# mc5_target_db register map
Vendor: Texas Instruments
Peripheral module from a debugger description file (folder iva2_arp32).
Address unit: 16 bits
Registers are 32-bit, read-write, reset 0x0 unless marked. A register's access mark holds for its fields unless they carry their own. Offsets are as the file gives them; lines under a group give offsets from that group; [hi:lo] are bit positions; {n}, {i} and the like mark numbered series; 'fields as' and 'values as' point back to an identical list; <NAME> marks a mode.

## DSS — ipxact12_to_ccs_generated
0x00 __ALL___SL2_BUF_ADDR_SKIP access per field reset 0x6000 — Skip Pred MB Base Address
  [21:0] BUF_ADDR rw — SL2 Base Address (128b word aligned) for Skip Pred MB
0x04 __ALL___SL2_BUF_ADDR_MBHDRINFO_TOP access per field — MB Info (Part-I) Base Address TOP
  [21:0] BUF_ADDR rw — SL2 Base Address (128b word aligned) for MB Info (Part-I) TOP
0x08 __ALL___SL2_BUF_ADDR_MBHDRINFO_BOT access per field reset 0x800 — MB Info (Part-I) Base Address BOT
  [21:0] BUF_ADDR rw — SL2 Base Address (128b word aligned) for MB Info (Part-I) BOT
0x0C __ALL___SL2_BUF_ADDR_MBMVINFO_TOP access per field reset 0x1000 — MV Info (Part-II) Base Address TOP
  [21:0] BUF_ADDR rw — SL2 Base Address (128b word aligned) for MV Info (Part-II) TOP
0x10 __ALL___SL2_BUF_ADDR_MBMVINFO_BOT access per field reset 0x1800 — MV Info (Part-II) Base Address BOT
  [21:0] BUF_ADDR rw — SL2 Base Address (128b word aligned) for MV Info (Part-II) BOT
0x14 __ALL___SL2_BUF_ADDR_SLICEINFO access per field reset 0x2000 — Slice Info Base Address
  [21:0] BUF_ADDR rw — SL2 Base Address (128b word aligned) for Slice Info
0x18 __ALL___SL2_BUF_ADDR_SLICEEXPWEIGHTTABLE access per field reset 0x3000 — Weighted Prediction Paremeters Base Address
  [21:0] BUF_ADDR rw — SL2 Base Address (128b word aligned) for Weighted Prediction Paremeters
0x1C __ALL___SL2_BUF_ADDR_SLICERPL access per field reset 0x4000 — Reference Picture List Base Address
  [21:0] BUF_ADDR rw — SL2 Base Address (128b word aligned) for Reference Picture List
0x20 __ALL___SL2_BUF_ADDR_PICREFFRAMEINFO access per field reset 0x5000 — Reference Frame Info Base Address
  [21:0] BUF_ADDR rw — SL2 Base Address (128b word aligned) for Reference Frame Info
0x24 __ALL___SL2_BUF_ADDR_RFPB access per field — Reference Frame Parameter Buffer Base Address
  [21:0] BUF_ADDR rw — SL2 Base Address for Reference Frame Parameter Buffer
{0x28+4i} __ALL___SL2_BUF_ADDR_Y_VC_R{i} access per field (i=0..3) — Luma Vertical Cache Ref={i} SL2 Base Address
  [21:0] BUF_ADDR rw — SL2 Base Address for Luma Vertical Cache Ref={i}
{0x48+4i} __ALL___SL2_BUF_ADDR_UV_VC_R{i} access per field (i=0..3) — Chroma Vertical Cache Ref={i} SL2 Base Address
  [21:0] BUF_ADDR rw — SL2 Base Address for Chroma Vertical Cache Ref={i}
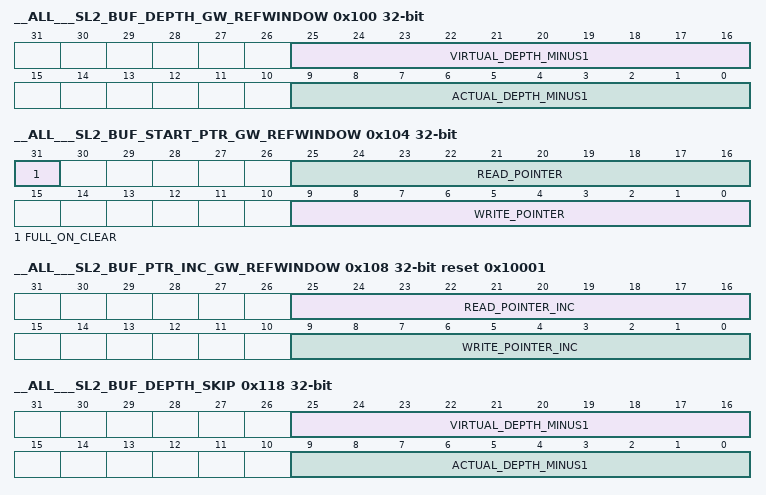
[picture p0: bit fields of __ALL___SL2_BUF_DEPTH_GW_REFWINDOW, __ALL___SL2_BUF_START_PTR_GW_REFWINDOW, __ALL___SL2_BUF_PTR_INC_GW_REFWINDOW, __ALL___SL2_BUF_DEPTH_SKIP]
0x100 __ALL___SL2_BUF_DEPTH_GW_REFWINDOW access per field — BC Control Parameters for Luma Growing Window Reference Pixel in SL2 fetched by iME
  [25:16] VIRTUAL_DEPTH_MINUS1 rw, [9:0] ACTUAL_DEPTH_MINUS1 rw
0x104 __ALL___SL2_BUF_START_PTR_GW_REFWINDOW access per field — BC Pointer Parameters for Luma Growing Window Reference Pixel in SL2 fetched by iME
  [31] FULL_ON_CLEAR rw, [25:16] READ_POINTER rw, [9:0] WRITE_POINTER rw
0x108 __ALL___SL2_BUF_PTR_INC_GW_REFWINDOW access per field reset 0x10001 — BC Pointer Increment Parameters for Luma Growing Window Reference Pixel in SL2 fetched by iME
  [25:16] READ_POINTER_INC rw, [9:0] WRITE_POINTER_INC rw
0x118 __ALL___SL2_BUF_DEPTH_SKIP access per field — BC Control Parameters for Luma Skip Pred Pixel in SL2 produced by iME
  [25:16] VIRTUAL_DEPTH_MINUS1 rw, [9:0] ACTUAL_DEPTH_MINUS1 rw
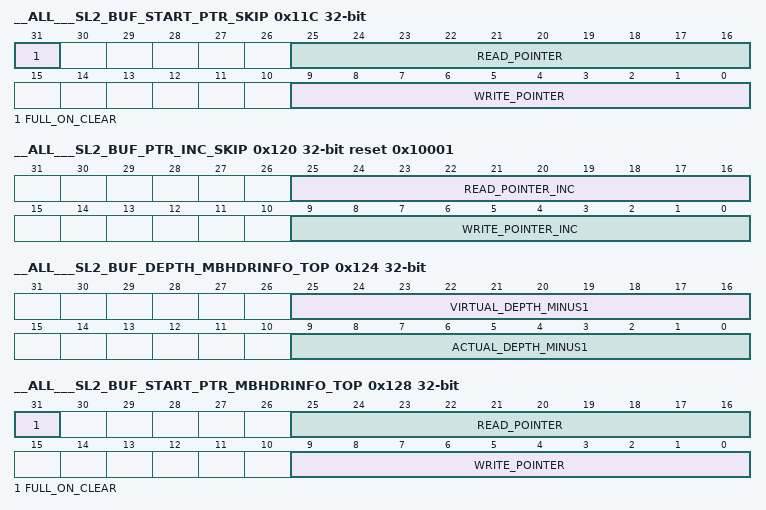
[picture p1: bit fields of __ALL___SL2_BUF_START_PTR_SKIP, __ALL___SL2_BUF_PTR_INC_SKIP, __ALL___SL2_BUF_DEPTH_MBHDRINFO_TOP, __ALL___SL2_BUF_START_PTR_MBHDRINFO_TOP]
0x11C __ALL___SL2_BUF_START_PTR_SKIP access per field — BC Pointer Parameters for Luma Skip Pred Pixel in SL2 produced by iME
  fields as __ALL___SL2_BUF_START_PTR_GW_REFWINDOW
0x120 __ALL___SL2_BUF_PTR_INC_SKIP access per field reset 0x10001 — BC Pointer Increment Parameters for Luma Skip Pred Pixel in SL2 produced by iME
  [25:16] READ_POINTER_INC rw, [9:0] WRITE_POINTER_INC rw
0x124 __ALL___SL2_BUF_DEPTH_MBHDRINFO_TOP access per field — BC Control Parameters for Top MB Level Information - part-I and part-II
  [25:16] VIRTUAL_DEPTH_MINUS1 rw, [9:0] ACTUAL_DEPTH_MINUS1 rw
0x128 __ALL___SL2_BUF_START_PTR_MBHDRINFO_TOP access per field — BC Pointer Parameters for Top MB Level Information - part-I and part-II
  fields as __ALL___SL2_BUF_START_PTR_GW_REFWINDOW
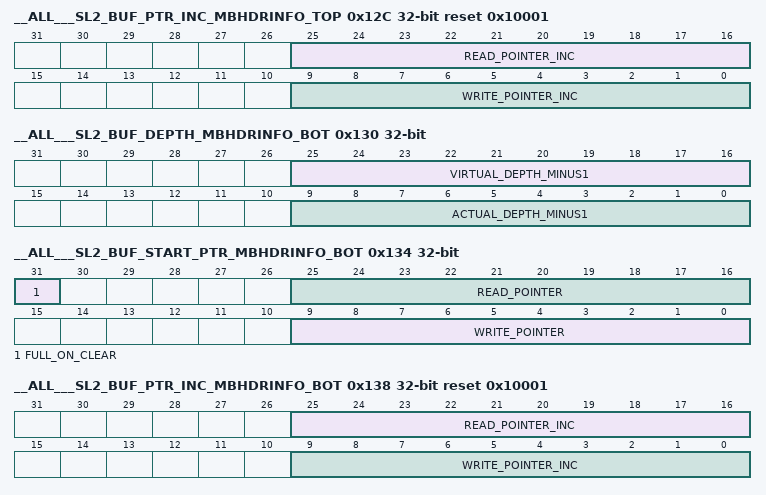
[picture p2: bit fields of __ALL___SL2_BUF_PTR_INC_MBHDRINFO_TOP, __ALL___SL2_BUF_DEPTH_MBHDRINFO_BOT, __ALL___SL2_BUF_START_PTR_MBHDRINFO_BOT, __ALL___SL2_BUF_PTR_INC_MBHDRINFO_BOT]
0x12C __ALL___SL2_BUF_PTR_INC_MBHDRINFO_TOP access per field reset 0x10001 — BC Pointer Increment Parameters for Top MB Level Information - part-I and part-II
  [25:16] READ_POINTER_INC rw, [9:0] WRITE_POINTER_INC rw
0x130 __ALL___SL2_BUF_DEPTH_MBHDRINFO_BOT access per field — BC Control Parameters for Bottom MB Level Information - part-I and part-II
  [25:16] VIRTUAL_DEPTH_MINUS1 rw, [9:0] ACTUAL_DEPTH_MINUS1 rw
0x134 __ALL___SL2_BUF_START_PTR_MBHDRINFO_BOT access per field — BC Pointer Parameters for Bottom MB Level Information - part-I and part-II
  fields as __ALL___SL2_BUF_START_PTR_GW_REFWINDOW
0x138 __ALL___SL2_BUF_PTR_INC_MBHDRINFO_BOT access per field reset 0x10001 — BC Pointer Increment Parameters for Bottom MB Level Information - part-I and part-II
  [25:16] READ_POINTER_INC rw, [9:0] WRITE_POINTER_INC rw
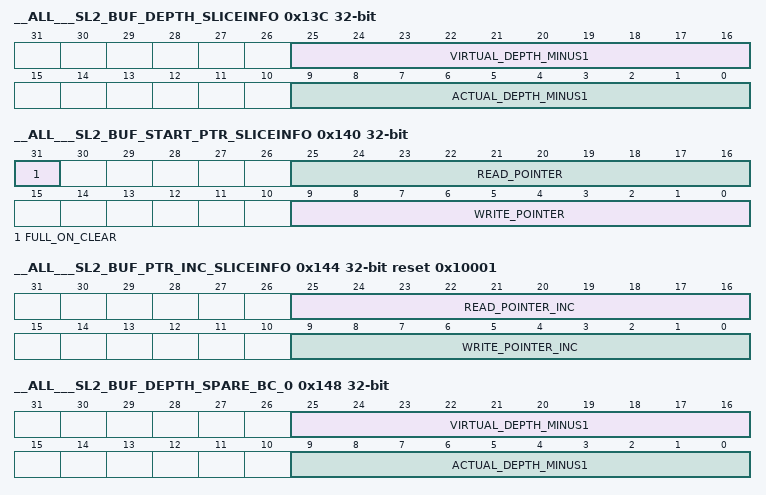
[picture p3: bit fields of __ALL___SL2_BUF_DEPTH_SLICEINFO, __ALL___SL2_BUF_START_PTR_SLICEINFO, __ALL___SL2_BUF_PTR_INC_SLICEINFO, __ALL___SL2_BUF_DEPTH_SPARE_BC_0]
0x13C __ALL___SL2_BUF_DEPTH_SLICEINFO access per field — BC Control Parameters for Slice Level Info - Slice_Info
  [25:16] VIRTUAL_DEPTH_MINUS1 rw, [9:0] ACTUAL_DEPTH_MINUS1 rw
0x140 __ALL___SL2_BUF_START_PTR_SLICEINFO access per field — BC Pointer Parameters for Slice Level Info - Slice_Info
  fields as __ALL___SL2_BUF_START_PTR_GW_REFWINDOW
0x144 __ALL___SL2_BUF_PTR_INC_SLICEINFO access per field reset 0x10001 — BC Pointer Increment Parameters for Slice Level Info - Slice_Info
  [25:16] READ_POINTER_INC rw, [9:0] WRITE_POINTER_INC rw
0x148 __ALL___SL2_BUF_DEPTH_SPARE_BC_0 access per field — BC Control Parameters for SPARE BC# 0
  [25:16] VIRTUAL_DEPTH_MINUS1 rw, [9:0] ACTUAL_DEPTH_MINUS1 rw
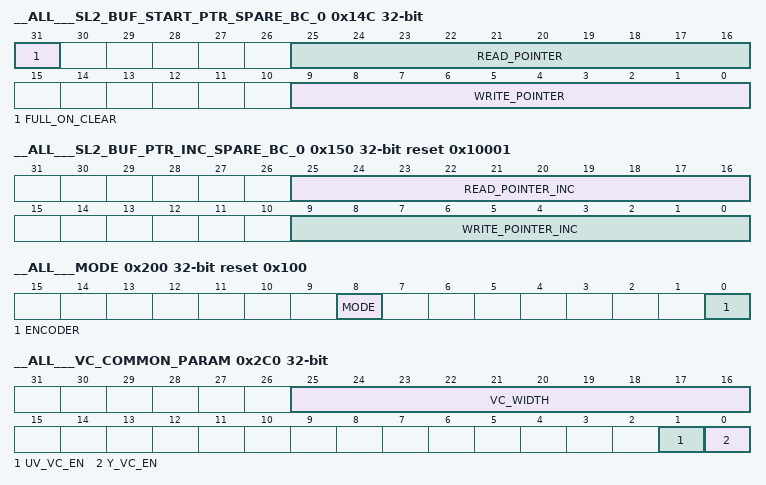
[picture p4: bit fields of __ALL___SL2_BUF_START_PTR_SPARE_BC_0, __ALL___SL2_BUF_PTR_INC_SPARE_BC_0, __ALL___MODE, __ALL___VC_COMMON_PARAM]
0x14C __ALL___SL2_BUF_START_PTR_SPARE_BC_0 access per field — BC Pointer Parameters for SPARE BC# 0
  fields as __ALL___SL2_BUF_START_PTR_GW_REFWINDOW
0x150 __ALL___SL2_BUF_PTR_INC_SPARE_BC_0 access per field reset 0x10001 — BC Pointer Increment Parameters for SPARE BC# 0
  [25:16] READ_POINTER_INC rw, [9:0] WRITE_POINTER_INC rw
0x200 __ALL___MODE access per field reset 0x100 — MC5 Mode Register
  [8] MODE rw — 0=>H.241, 1=>Normal
  [0] ENCODER rw — 0=>Decoder, 1=>Encoder
0x204 __ALL___CODEC_TYPE access per field — MC5 codec type register
  [3:0] CODEC_TYPE rw — 0=>H.264, Others=>Reserved
0x208 __ALL___MC5_PARAMETER_1 access per field reset 0x4000 — MC5 Paremeters 1
  [15:0] Y_DDR_STRIDE rw — DDR Stride for Luma Component
0x20C __ALL___MC5_PARAMETER_2 access per field reset 0x8000 — MC5 Paremeters 2
  [15:0] UV_DDR_STRIDE rw — DDR Stride for Chroma Component
0x210 __ALL___MC5_PARAMETER_3 access per field — MC5 Paremeters 3
  [1:0] SUB_TILE_TYPE rw — Type of DDR Sub-tile, 0->4x4, 1->8x4
0x214 __ALL___MC5_PARAMETER_4 access per field — MC5 Paremeters 4
  [0] NV21 rw — 1 = NV21 mode of operation; 0 (default) = NV12
0x218 __ALL___MC5_PARAMETER_5 access per field reset 0x3 — MC5 Paremeters 5
  [1:0] MAX_N_MB_MINUS1 rw — Maximum value of n-MB - 1
0x21C __ALL___MC5_PARAMETER_6 access per field — MC5 Paremeters 6
  [0] CACHE_BYPASS rw — No Caching done by MC5
0x220 __ALL___MC5_PARAMETER_7 access per field reset 0x200 — MC5 Paremeters 7
  [15:0] MV_BUF_SIZE rw — Size of entire MV Buffer in SL2 - applies for both odd and even
0x224 __ALL___MC5_PARAMETER_8 access per field — MC5 Paremeters 8
  [0] SEC_MERGE_BYPASS rw — 1 = No Secondary Merging is performed
0x228 __ALL___MC5_PARAMETER_9 access per field — MC5 Paremeters 9
  [0] ARBITRARY_START rw — 1 => We started decoding a stream at an arbitrary point and dpb is empty. MC5 should operate like intra MB for entire picture.
0x280 __ALL___ENCODER_PARAMETER_1 access per field — MC5 Encoder Parameters 1
  [0] BSKIP_PRED_BY_IME rw — B-Skip Data Prepared by iME
0x2C0 __ALL___VC_COMMON_PARAM access per field — Vertical Cache Parameters
  [25:16] VC_WIDTH rw — Luma Vertical Cache Width
  [1] UV_VC_EN rw — Chroma Vertical Cache Enable
  [0] Y_VC_EN rw — Luma Vertical Cache Enable
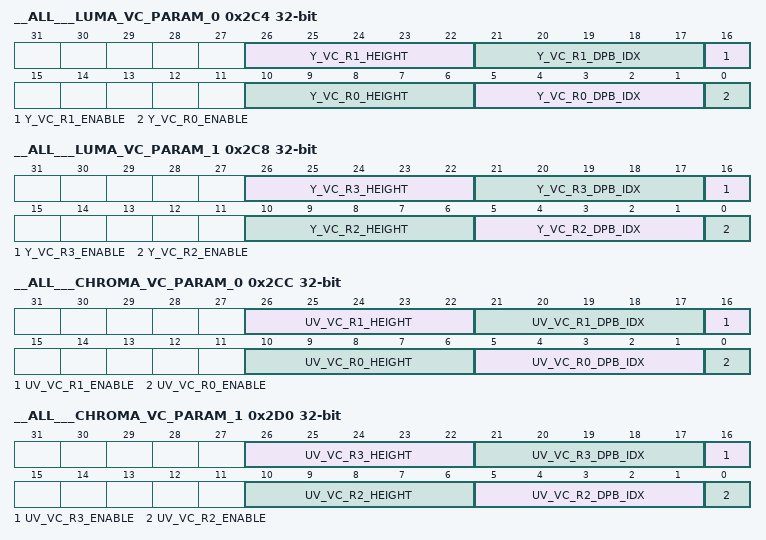
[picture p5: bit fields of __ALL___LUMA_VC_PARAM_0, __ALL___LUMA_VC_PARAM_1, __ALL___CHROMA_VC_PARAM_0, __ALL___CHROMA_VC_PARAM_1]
0x2C4 __ALL___LUMA_VC_PARAM_0 access per field — Luma Vertical Cache Parameters #0
  [26:22] Y_VC_R1_HEIGHT rw — Luma Vertical Cache for Ref# 1 Vertical Search Range(VSR) in multiples of 8 pixels; Height = 2*VSR+16
  [21:17] Y_VC_R1_DPB_IDX rw — Luma Vertical Cache for Ref# 1 DPB Index
  [16] Y_VC_R1_ENABLE rw — Luma Vertical Cache for Ref# 1 Enable
  [10:6] Y_VC_R0_HEIGHT rw — Luma Vertical Cache for Ref# 0 Vertical Search Range(VSR) in multiples of 8 pixels; Height = 2*VSR+16
  [5:1] Y_VC_R0_DPB_IDX rw — Luma Vertical Cache for Ref# 0 DPB Index
  [0] Y_VC_R0_ENABLE rw — Luma Vertical Cache for Ref# 0 Enable
0x2C8 __ALL___LUMA_VC_PARAM_1 access per field — Luma Vertical Cache Parameters #1
  [26:22] Y_VC_R3_HEIGHT rw — Luma Vertical Cache for Ref# 3 Vertical Search Range(VSR) in multiples of 8 pixels; Height = 2*VSR+16
  [21:17] Y_VC_R3_DPB_IDX rw — Luma Vertical Cache for Ref# 3 DPB Index
  [16] Y_VC_R3_ENABLE rw — Luma Vertical Cache for Ref# 3 Enable
  [10:6] Y_VC_R2_HEIGHT rw — Luma Vertical Cache for Ref# 2 Vertical Search Range(VSR) in multiples of 8 pixels; Height = 2*VSR+16
  [5:1] Y_VC_R2_DPB_IDX rw — Luma Vertical Cache for Ref# 2 DPB Index
  [0] Y_VC_R2_ENABLE rw — Luma Vertical Cache for Ref# 2 Enable
0x2CC __ALL___CHROMA_VC_PARAM_0 access per field — Chroma Vertical Cache Parameters #0
  [26:22] UV_VC_R1_HEIGHT rw — Chroma Vertical Cache for Ref# 1 Vertical Search Range(VSR) in multiples of 4 pixels; Height = 2*VSR+8
  [21:17] UV_VC_R1_DPB_IDX rw — Chroma Vertical Cache for Ref# 1 DPB Index
  [16] UV_VC_R1_ENABLE rw — Chroma Vertical Cache for Ref# 1 Enable
  [10:6] UV_VC_R0_HEIGHT rw — Chroma Vertical Cache for Ref# 0 Vertical Search Range(VSR) in multiples of 4 pixels; Height = 2*VSR+8
  [5:1] UV_VC_R0_DPB_IDX rw — Chroma Vertical Cache for Ref# 0 DPB Index
  [0] UV_VC_R0_ENABLE rw — Chroma Vertical Cache for Ref# 0 Enable
0x2D0 __ALL___CHROMA_VC_PARAM_1 access per field — Chroma Vertical Cache Parameters #1
  [26:22] UV_VC_R3_HEIGHT rw — Chroma Vertical Cache for Ref# 3 Vertical Search Range(VSR) in multiples of 4 pixels; Height = 2*VSR+8
  [21:17] UV_VC_R3_DPB_IDX rw — Chroma Vertical Cache for Ref# 3 DPB Index
  [16] UV_VC_R3_ENABLE rw — Chroma Vertical Cache for Ref# 3 Enable
  [10:6] UV_VC_R2_HEIGHT rw — Chroma Vertical Cache for Ref# 2 Vertical Search Range(VSR) in multiples of 4 pixels; Height = 2*VSR+8
  [5:1] UV_VC_R2_DPB_IDX rw — Chroma Vertical Cache for Ref# 2 DPB Index
  [0] UV_VC_R2_ENABLE rw — Chroma Vertical Cache for Ref# 2 Enable
0x300 __ALL___MB_INF_CONTEXT access per field — A register which defines which SL2BC MBInfo comes from
  [0] MB_INF_START_O_NE rw — MB Info read from odd or even SL2BC; 0-> Even, 1-> Odd
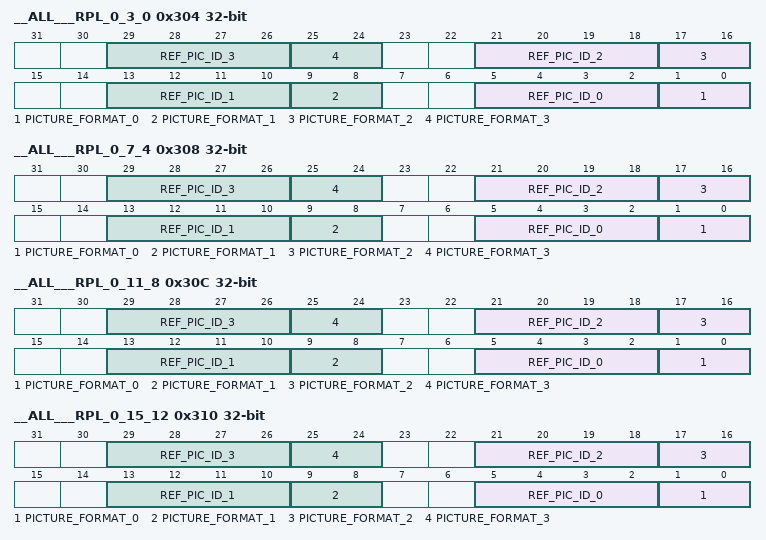
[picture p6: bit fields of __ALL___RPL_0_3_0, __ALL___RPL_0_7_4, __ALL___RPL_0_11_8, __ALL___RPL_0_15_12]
0x304 __ALL___RPL_0_3_0 access per field — 32 bit RPL word
  [8n+5:8n+2] REF_PIC_ID_{n} rw (n=0..3) — equal the reference frame ID of ref_idx={n} in L0
  [8n+1:8n] PICTURE_FORMAT_{n} rw (n=0..3) — 0: frame picture, 1: top-field picture, 2: bottom-field picture, 3: Reserved.
0x308 __ALL___RPL_0_7_4 access per field — 32 bit RPL word
  [8n+5:8n+2] REF_PIC_ID_{n} rw (n=0..3) — equal the reference frame ID of ref_idx={n+4} in L0
  [8n+1:8n] PICTURE_FORMAT_{n} rw (n=0..3) — 0: frame picture, 1: top-field picture, 2: bottom-field picture, 3: Reserved.
0x30C __ALL___RPL_0_11_8 access per field — 32 bit RPL word
  [8n+5:8n+2] REF_PIC_ID_{n} rw (n=0..3) — equal the reference frame ID of ref_idx={n+8} in L0
  [8n+1:8n] PICTURE_FORMAT_{n} rw (n=0..3) — 0: frame picture, 1: top-field picture, 2: bottom-field picture, 3: Reserved.
0x310 __ALL___RPL_0_15_12 access per field — 32 bit RPL word
  [8n+5:8n+2] REF_PIC_ID_{n} rw (n=0..3) — equal the reference frame ID of ref_idx={n+12} in L0
  [8n+1:8n] PICTURE_FORMAT_{n} rw (n=0..3) — 0: frame picture, 1: top-field picture, 2: bottom-field picture, 3: Reserved.
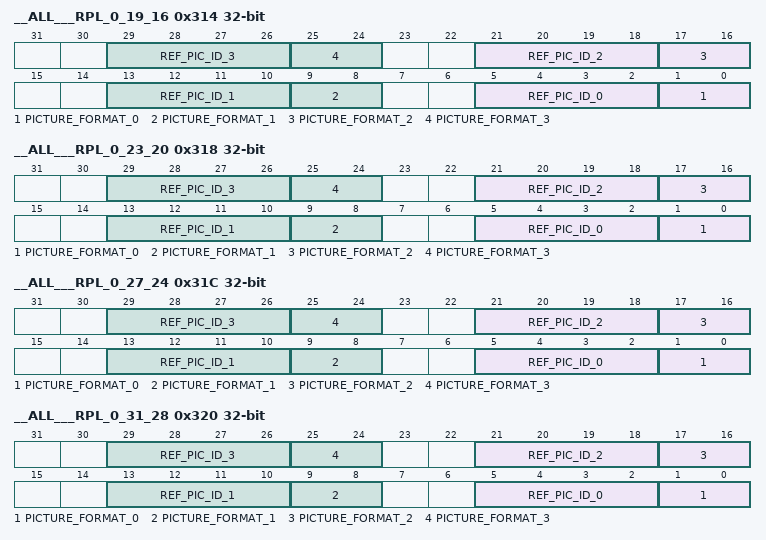
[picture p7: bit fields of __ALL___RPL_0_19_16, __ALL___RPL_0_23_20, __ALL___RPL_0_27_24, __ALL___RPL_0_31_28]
0x314 __ALL___RPL_0_19_16 access per field — 32 bit RPL word
  [8n+5:8n+2] REF_PIC_ID_{n} rw (n=0..3) — equal the reference frame ID of ref_idx={n+16} in L0
  [8n+1:8n] PICTURE_FORMAT_{n} rw (n=0..3) — 0: frame picture, 1: top-field picture, 2: bottom-field picture, 3: Reserved.
0x318 __ALL___RPL_0_23_20 access per field — 32 bit RPL word
  [8n+5:8n+2] REF_PIC_ID_{n} rw (n=0..3) — equal the reference frame ID of ref_idx={n+20} in L0
  [8n+1:8n] PICTURE_FORMAT_{n} rw (n=0..3) — 0: frame picture, 1: top-field picture, 2: bottom-field picture, 3: Reserved.
0x31C __ALL___RPL_0_27_24 access per field — 32 bit RPL word
  [8n+5:8n+2] REF_PIC_ID_{n} rw (n=0..3) — equal the reference frame ID of ref_idx={n+24} in L0
  [8n+1:8n] PICTURE_FORMAT_{n} rw (n=0..3) — 0: frame picture, 1: top-field picture, 2: bottom-field picture, 3: Reserved.
0x320 __ALL___RPL_0_31_28 access per field — 32 bit RPL word
  [8n+5:8n+2] REF_PIC_ID_{n} rw (n=0..3) — equal the reference frame ID of ref_idx={n+28} in L0
  [8n+1:8n] PICTURE_FORMAT_{n} rw (n=0..3) — 0: frame picture, 1: top-field picture, 2: bottom-field picture, 3: Reserved.
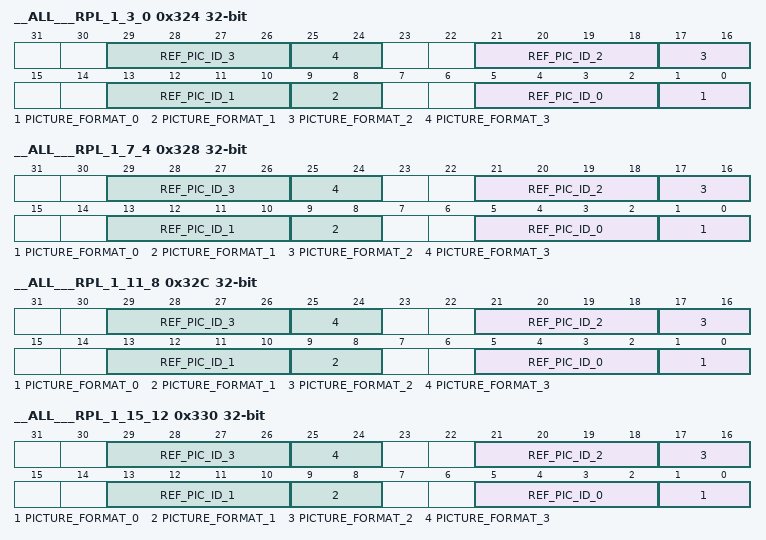
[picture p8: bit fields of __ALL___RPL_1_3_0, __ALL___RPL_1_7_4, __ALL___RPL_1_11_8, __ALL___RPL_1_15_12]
0x324 __ALL___RPL_1_3_0 access per field — 32 bit RPL word
  [8n+5:8n+2] REF_PIC_ID_{n} rw (n=0..3) — equal the reference frame ID of ref_idx={n} in L1
  [8n+1:8n] PICTURE_FORMAT_{n} rw (n=0..3) — 0: frame picture, 1: top-field picture, 2: bottom-field picture, 3: Reserved.
0x328 __ALL___RPL_1_7_4 access per field — 32 bit RPL word
  [8n+5:8n+2] REF_PIC_ID_{n} rw (n=0..3) — equal the reference frame ID of ref_idx={n+4} in L1
  [8n+1:8n] PICTURE_FORMAT_{n} rw (n=0..3) — 0: frame picture, 1: top-field picture, 2: bottom-field picture, 3: Reserved.
0x32C __ALL___RPL_1_11_8 access per field — 32 bit RPL word
  [8n+5:8n+2] REF_PIC_ID_{n} rw (n=0..3) — equal the reference frame ID of ref_idx={n+8} in L1
  [8n+1:8n] PICTURE_FORMAT_{n} rw (n=0..3) — 0: frame picture, 1: top-field picture, 2: bottom-field picture, 3: Reserved.
0x330 __ALL___RPL_1_15_12 access per field — 32 bit RPL word
  [8n+5:8n+2] REF_PIC_ID_{n} rw (n=0..3) — equal the reference frame ID of ref_idx={n+12} in L1
  [8n+1:8n] PICTURE_FORMAT_{n} rw (n=0..3) — 0: frame picture, 1: top-field picture, 2: bottom-field picture, 3: Reserved.
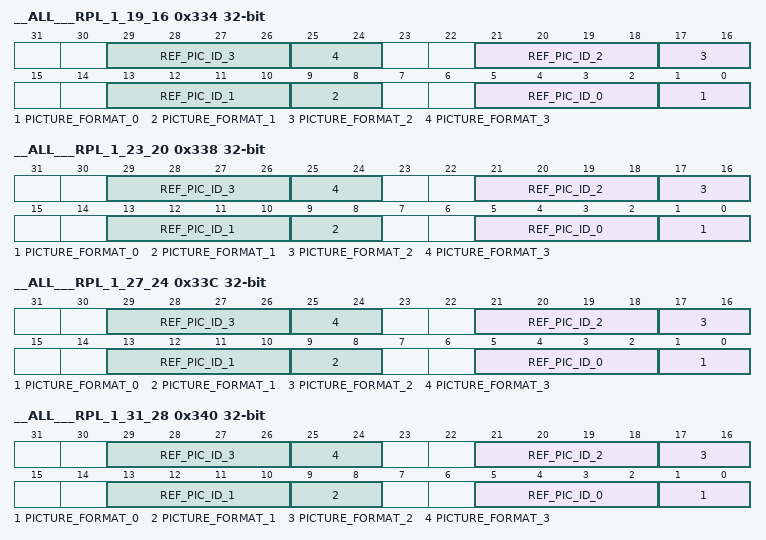
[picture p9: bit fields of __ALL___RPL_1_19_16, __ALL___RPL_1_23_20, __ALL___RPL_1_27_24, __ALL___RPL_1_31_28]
0x334 __ALL___RPL_1_19_16 access per field — 32 bit RPL word
  [8n+5:8n+2] REF_PIC_ID_{n} rw (n=0..3) — equal the reference frame ID of ref_idx={n+16} in L1
  [8n+1:8n] PICTURE_FORMAT_{n} rw (n=0..3) — 0: frame picture, 1: top-field picture, 2: bottom-field picture, 3: Reserved.
0x338 __ALL___RPL_1_23_20 access per field — 32 bit RPL word
  [8n+5:8n+2] REF_PIC_ID_{n} rw (n=0..3) — equal the reference frame ID of ref_idx={n+20} in L1
  [8n+1:8n] PICTURE_FORMAT_{n} rw (n=0..3) — 0: frame picture, 1: top-field picture, 2: bottom-field picture, 3: Reserved.
0x33C __ALL___RPL_1_27_24 access per field — 32 bit RPL word
  [8n+5:8n+2] REF_PIC_ID_{n} rw (n=0..3) — equal the reference frame ID of ref_idx={n+24} in L1
  [8n+1:8n] PICTURE_FORMAT_{n} rw (n=0..3) — 0: frame picture, 1: top-field picture, 2: bottom-field picture, 3: Reserved.
0x340 __ALL___RPL_1_31_28 access per field — 32 bit RPL word
  [8n+5:8n+2] REF_PIC_ID_{n} rw (n=0..3) — equal the reference frame ID of ref_idx={n+28} in L1
  [8n+1:8n] PICTURE_FORMAT_{n} rw (n=0..3) — 0: frame picture, 1: top-field picture, 2: bottom-field picture, 3: Reserved.
0x400 __ALL___PID ro — MC5 PID
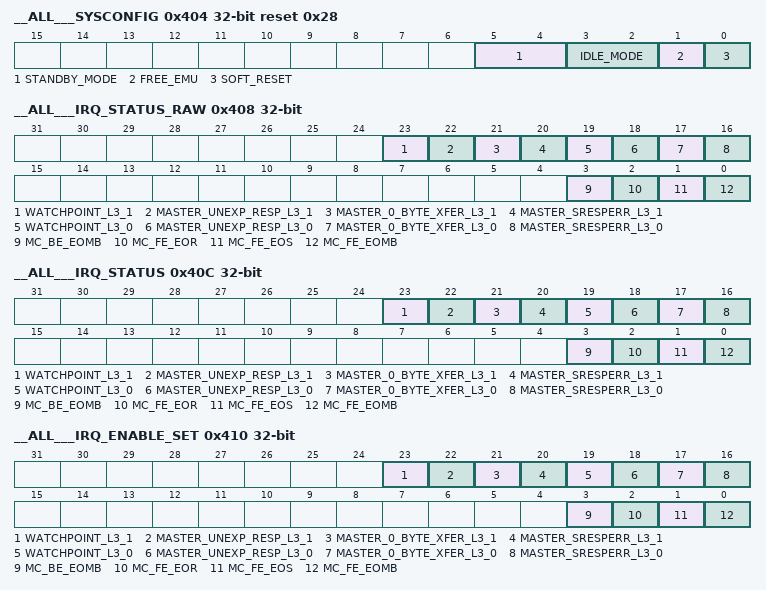
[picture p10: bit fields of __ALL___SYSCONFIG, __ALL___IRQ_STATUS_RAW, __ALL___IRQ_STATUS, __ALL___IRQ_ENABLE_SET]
0x404 __ALL___SYSCONFIG access per field reset 0x28 — SYSCONFIG
  [5:4] STANDBY_MODE rw, [3:2] IDLE_MODE rw, [1] FREE_EMU rw, [0] SOFT_RESET rw
0x408 __ALL___IRQ_STATUS_RAW access per field — Raw status of sources. Raw status is set even if the interrupt is not enabled; Write 1 to set the raw status (mostly for debug) The following is the behavior for read/write into each of the individual fields : Write 0: No action Write 1: Set event (for debug) Read 0: No event pending Read 1: Event pending
  [23] WATCHPOINT_L3_1 rw — Watch-point for L3 port #1 interrupt raw status
  [22] MASTER_UNEXP_RESP_L3_1 rw — Unexpected response received from L3 master port #1 interrupt raw status
  [21] MASTER_0_BYTE_XFER_L3_1 rw — MC-DMA OCP L3 master port (#1) send command for zero byte transfer interrupt raw status
  [20] MASTER_SRESPERR_L3_1 rw — MC-DMA OCP L3 master port (#1) received Sresp=ERR from platform interrupt raw status
  [19] WATCHPOINT_L3_0 rw — Watch-point for L3 port #0 interrupt raw status
  [18] MASTER_UNEXP_RESP_L3_0 rw — Unexpected response received from L3 master port #0 interrupt raw status
  [17] MASTER_0_BYTE_XFER_L3_0 rw — MC-DMA OCP L3 master port (#0) send command for zero byte transfer interrupt raw status
  [16] MASTER_SRESPERR_L3_0 rw — MC-DMA OCP L3 master port (#0) received Sresp=ERR from platform interrupt raw status
  [3] MC_BE_EOMB rw — MC Back-end end of MB interrupt raw status
  [2] MC_FE_EOR rw — MC FE end of row interrupt raw status
  [1] MC_FE_EOS rw — MC FE end of slice interrupt raw status
  [0] MC_FE_EOMB rw — MC FE end of MB interrupt raw status
0x40C __ALL___IRQ_STATUS access per field — Status of enabled sources. The individual status bits are not set, unless the source is enabled (by setting corresponding bit in IRQ_ENABLE_SET register) Write "1" to specific bit in this register to clear the status after interrupt has been serviced. Note : Writing "1" clears the "raw" status as well Note : Writing "1" generates internal EOI. The interrupt line is pulsed again, if any of the interrupt sources are still active (any of the status bits are "1") after the write of "1". The following is the behavior for read/write into each of the individual fields : Write 0: No action Write 1: Clear (raw) event - clears the corresponding bit in this register as well as the "raw" status bit in the IRQ_STATUS_RAW register Read 0: No enabled event pending Read 1: Event pending
  [23] WATCHPOINT_L3_1 rw — Watch-point for L3 port #1 interrupt status
  [22] MASTER_UNEXP_RESP_L3_1 rw — Unexpected response received from L3 master port #1 interrupt status
  [21] MASTER_0_BYTE_XFER_L3_1 rw — MC-DMA OCP L3 master port (#1) send command for zero byte transfer interrupt status
  [20] MASTER_SRESPERR_L3_1 rw — MC-DMA OCP L3 master port (#1) received Sresp=ERR from platform interrupt status
  [19] WATCHPOINT_L3_0 rw — Watch-point for L3 port #0 interrupt status
  [18] MASTER_UNEXP_RESP_L3_0 rw — Unexpected response received from L3 master port #0 interrupt status
  [17] MASTER_0_BYTE_XFER_L3_0 rw — MC-DMA OCP L3 master port (#0) send command for zero byte transfer interrupt status
  [16] MASTER_SRESPERR_L3_0 rw — MC-DMA OCP L3 master port (#0) received Sresp=ERR from platform interrupt status
  [3] MC_BE_EOMB rw — MC Back-end end of MB interrupt status
  [2] MC_FE_EOR rw — MC FE end of row interrupt status
  [1] MC_FE_EOS rw — MC FE end of slice interrupt status
  [0] MC_FE_EOMB rw — MC FE end of MB interrupt status
0x410 __ALL___IRQ_ENABLE_SET access per field — Interrupt enable for each of the sources. Writing "1" to specific field in this register enables the corresponding source for interrupt generatation The read value reflects whether the corresponding source is enabled/disabled for interrupt generation The following is the behavior for read/write into each of the individual fields : Write 0: No action Write 1: Enable interrupt Read 0: Interrupt disabled (masked) Read 1: Interrupt enabled
  [23] WATCHPOINT_L3_1 rw — Watch-point for L3 port #1 interrupt enable set
  [22] MASTER_UNEXP_RESP_L3_1 rw — Unexpected response received from L3 master port #1 interrupt enable set
  [21] MASTER_0_BYTE_XFER_L3_1 rw — MC-DMA OCP L3 master port (#1) send command for zero byte transfer interrupt enable set
  [20] MASTER_SRESPERR_L3_1 rw — MC-DMA OCP L3 master port (#1) received Sresp=ERR from platform interrupt enable set
  [19] WATCHPOINT_L3_0 rw — Watch-point for L3 port #0 interrupt enable set
  [18] MASTER_UNEXP_RESP_L3_0 rw — Unexpected response received from L3 master port #0 interrupt enable set
  [17] MASTER_0_BYTE_XFER_L3_0 rw — MC-DMA OCP L3 master port (#0) send command for zero byte transfer interrupt enable set
  [16] MASTER_SRESPERR_L3_0 rw — MC-DMA OCP L3 master port (#0) received Sresp=ERR from platform interrupt enable set
  [3] MC_BE_EOMB rw — MC Back-end end of MB interrupt enable set
  [2] MC_FE_EOR rw — MC FE end of row interrupt enable set
  [1] MC_FE_EOS rw — MC FE end of slice interrupt enable set
  [0] MC_FE_EOMB rw — MC FE end of MB interrupt enable set
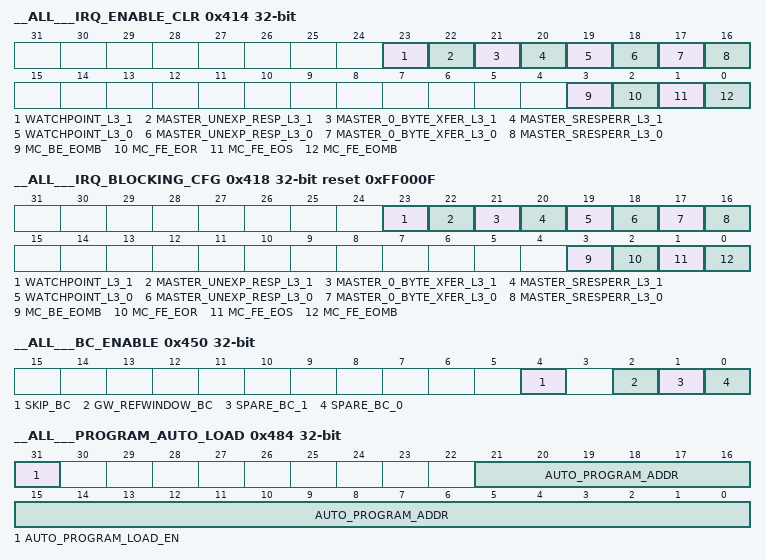
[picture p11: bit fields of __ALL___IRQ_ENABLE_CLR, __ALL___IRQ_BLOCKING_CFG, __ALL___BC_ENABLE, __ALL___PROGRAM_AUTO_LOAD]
0x414 __ALL___IRQ_ENABLE_CLR access per field — Interrupt disable for each of the sources. Writing "1" to specific field in this register disables the corresponding source for interrupt generatation The read value reflects whether the corresponding source is enabled/disabled for interrupt generation The following is the behavior for read/write into each of the individual fields : Write 0: No action Write 1: Disable interrupt Read 0: Interrupt disabled (masked) Read 1: Interrupt enabled
  [23] WATCHPOINT_L3_1 rw — Watch-point for L3 port #1 interrupt enable clear
  [22] MASTER_UNEXP_RESP_L3_1 rw — Unexpected response received from L3 master port #1 interrupt enable clear
  [21] MASTER_0_BYTE_XFER_L3_1 rw — MC-DMA OCP L3 master port (#1) send command for zero byte transfer interrupt enable clear
  [20] MASTER_SRESPERR_L3_1 rw — MC-DMA OCP L3 master port (#1) received Sresp=ERR from platform interrupt enable clear
  [19] WATCHPOINT_L3_0 rw — Watch-point for L3 port #0 interrupt enable clear
  [18] MASTER_UNEXP_RESP_L3_0 rw — Unexpected response received from L3 master port #0 interrupt enable clear
  [17] MASTER_0_BYTE_XFER_L3_0 rw — MC-DMA OCP L3 master port (#0) send command for zero byte transfer interrupt enable clear
  [16] MASTER_SRESPERR_L3_0 rw — MC-DMA OCP L3 master port (#0) received Sresp=ERR from platform interrupt enable clear
  [3] MC_BE_EOMB rw — MC Back-end end of MB interrupt enable clear
  [2] MC_FE_EOR rw — MC FE end of row interrupt enable clear
  [1] MC_FE_EOS rw — MC FE end of slice interrupt enable clear
  [0] MC_FE_EOMB rw — MC FE end of MB interrupt enable clear
0x418 __ALL___IRQ_BLOCKING_CFG access per field reset 0xFF000F — Interrupt blocking configuration for each of the sources. If a bit in this register is set to "1", MC5 halts after it generates an interrupt for the corresponding interrupt source, and waits for interrupt acknowledgement for that interrupt line before continuing execution. If a bit in this register is set to "0", MC5 does not halt after it generates an interrupt for the corresponding interrupt source. The configuration in this register only apply to enabled interrupt sources.
  [23] WATCHPOINT_L3_1 rw — Watch-point for L3 port #1 interrupt blocking enabled
  [22] MASTER_UNEXP_RESP_L3_1 rw — Unexpected response received from L3 master port #1 interrupt blocking enabled
  [21] MASTER_0_BYTE_XFER_L3_1 rw — MC-DMA OCP L3 master port (#1) send command for zero byte transfer interrupt blocking enabled
  [20] MASTER_SRESPERR_L3_1 rw — MC-DMA OCP L3 master port (#1) received Sresp=ERR from platform interrupt blocking enabled
  [19] WATCHPOINT_L3_0 rw — Watch-point for L3 port #0 interrupt blocking enabled
  [18] MASTER_UNEXP_RESP_L3_0 rw — Unexpected response received from L3 master port #0 interrupt blocking enabled
  [17] MASTER_0_BYTE_XFER_L3_0 rw — MC-DMA OCP L3 master port (#0) send command for zero byte transfer interrupt blocking enabled
  [16] MASTER_SRESPERR_L3_0 rw — MC-DMA OCP L3 master port (#0) received Sresp=ERR from platform interrupt blocking enabled
  [3] MC_BE_EOMB rw — MC Back-end end of MB interrupt blocking enabled
  [2] MC_FE_EOR rw — MC FE end of row interrupt blocking enabled
  [1] MC_FE_EOS rw — MC FE end of slice interrupt blocking enabled
  [0] MC_FE_EOMB rw — MC FE end of MB interrupt blocking enabled
0x440 __ALL___DMA_WATCHPOINT_BOTTOM_BOUND — Watchpoint interrupt is raised when the DMA address on any L3 port is less than this bound.
  [31:0] L3_ADDRESS — Lower 32 bits of the address bound.
0x444 __ALL___DMA_WATCHPOINT_TOP_BOUND reset 0xFFFFFFFF — Watchpoint interrupt is raised when the DMA address on any L3 port is more than this bound.
  [31:0] L3_ADDRESS — Lower 32 bits of the address bound.
0x448 __ALL___WATCHPOINT_INTR_ADDRESS_L3_0 ro — L3 Port#0 Address which cause watch-point interrupt for L3 Port#0 (WATCHPOINT_L3_0)
  [31:0] L3_ADDRESS — Lower 32 bits of the address bound.
0x44C __ALL___WATCHPOINT_INTR_ADDRESS_L3_1 ro — L3 Port#1 Address which cause watch-point interrupt for L3 Port#1 (WATCHPOINT_L3_1)
  [31:0] L3_ADDRESS — Lower 32 bits of the address bound.
0x450 __ALL___BC_ENABLE access per field — Enable MMR for BCs in MC5. If this register is 0, the corresponding BC's ready is not looked for thread to proceed its execution
  [4] SKIP_BC rw — Enable for SKIP_BC; 1=>Enabled (BC Ready is required for thread to proceed); 0=>Disabled
  [2] GW_REFWINDOW_BC rw — Enable for GW_REFWINDOW_BC; 1=>Enabled (BC Ready is required for thread to proceed); 0=>Disabled
  [1] SPARE_BC_1 rw — Enable for Spare BC #1; 1=>Enabled (BC Ready is required for thread to proceed); 0=>Disabled
  [0] SPARE_BC_0 rw — Enable for Spare BC #0; 1=>Enabled (BC Ready is required for thread to proceed); 0=>Disabled
0x480 __ALL___MC5_ENABLE access per field — MC5 Enable
  [0] MC_EN rw
0x484 __ALL___PROGRAM_AUTO_LOAD access per field — Enable and SL2 location of the Auto Load MMR Image
  [31] AUTO_PROGRAM_LOAD_EN rw — 1 => Program Auto Load Enabled
  [21:0] AUTO_PROGRAM_ADDR rw — Program Auto Load SL2 Base Address
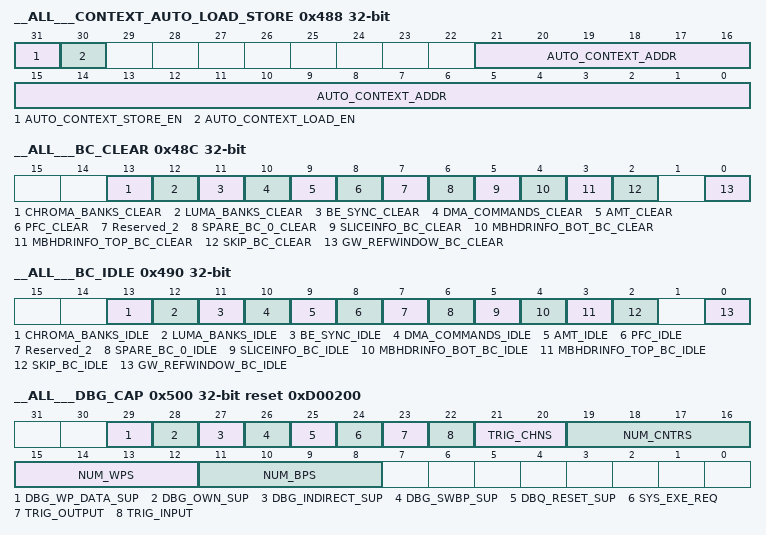
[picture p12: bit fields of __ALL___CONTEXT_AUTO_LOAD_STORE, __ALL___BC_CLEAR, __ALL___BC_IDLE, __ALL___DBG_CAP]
0x488 __ALL___CONTEXT_AUTO_LOAD_STORE access per field — Enable and SL2 location of the Context MMR Image
  [31] AUTO_CONTEXT_STORE_EN rw — 1 => Cotext Auto Store Enabled
  [30] AUTO_CONTEXT_LOAD_EN rw — 1 => Cotext Auto Load Enabled
  [21:0] AUTO_CONTEXT_ADDR rw — Context Auto Load / Store SL2 Base Address
0x48C __ALL___BC_CLEAR access per field — BC Clear Register for LBC and SL2BC
  [13] CHROMA_BANKS_CLEAR wo — BC Clear for All Chroma Data Banks LBCs
  [12] LUMA_BANKS_CLEAR wo — BC Clear for All Luma Data Banks LBCs
  [11] BE_SYNC_CLEAR wo — BC Clear for BE SYNC LBC
  [10] DMA_COMMANDS_CLEAR wo — BC Clear for DMA Commands and DMA Internal Addres LBCs
  [9] AMT_CLEAR wo — BC Clear for AMT LBC
  [8] PFC_CLEAR wo — BC Clear for Filter Commands LBC
  [7] Reserved_2 wo — BC Clear for SPARE BC# 1
  [6] SPARE_BC_0_CLEAR wo — BC Clear for SPARE BC# 0
  [5] SLICEINFO_BC_CLEAR wo — BC Clear for SliceInfo SL2BC
  [4] MBHDRINFO_BOT_BC_CLEAR wo — BC Clear for Bottom MB Information SL2BC
  [3] MBHDRINFO_TOP_BC_CLEAR wo — BC Clear for Top MB Information SL2BC
  [2] SKIP_BC_CLEAR wo — BC Clear for Skip Pred Pixel SL2BC
  [0] GW_REFWINDOW_BC_CLEAR wo — BC Clear for Growing Window Reference Pixel SL2BC
0x490 __ALL___BC_IDLE access per field — BC Idle Register for LBC and SL2BC
  [13] CHROMA_BANKS_IDLE wo — BC idle for All Chroma Data Banks LBCs
  [12] LUMA_BANKS_IDLE wo — BC idle for All Luma Data Banks LBCs
  [11] BE_SYNC_IDLE wo — BC idle for BE SYNC LBC
  [10] DMA_COMMANDS_IDLE wo — BC idle for DMA Commands and DMA Internal Addres LBCs
  [9] AMT_IDLE wo — BC idle for AMT LBC
  [8] PFC_IDLE wo — BC idle for Filter Commands LBC
  [7] Reserved_2 wo — BC idle for SPARE BC# 1
  [6] SPARE_BC_0_IDLE wo — BC idle for SPARE BC# 0
  [5] SLICEINFO_BC_IDLE wo — BC idle for SliceInfo SL2BC
  [4] MBHDRINFO_BOT_BC_IDLE wo — BC idle for Bottom MB Information SL2BC
  [3] MBHDRINFO_TOP_BC_IDLE wo — BC idle for Top MB Information SL2BC
  [2] SKIP_BC_IDLE wo — BC idle for Skip Pred Pixel SL2BC
  [0] GW_REFWINDOW_BC_IDLE wo — BC idle for Growing Window Reference Pixel SL2BC
0x500 __ALL___DBG_CAP ro reset 0xD00200 — Debug Capability register is used by debug software to determine which optional debug modules are present and how many instances of each module exist.
  [29] DBG_WP_DATA_SUP — Indicates if the WP resources has corresponding data qualification. b0 - Not supported. b1 - Data qualifiers are supported.
  [28] DBG_OWN_SUP — Indicates if the HWA supports an module ownership. v2.0 and above. b0 - Not Supported. b1 - Ownership supported.
  [27] DBG_INDIRECT_SUP — Indicates if the HWA supports an indirect memory access port. v2.0 and above. b0 - Not Supported. b1 - Indirect port supported.
  [26] DBG_SWBP_SUP — Whether HWA Core supports SWBP or not. b0 - Not Supported. b1 - Supported.
  [25] DBQ_RESET_SUP — Whether HWA Core reset is supported or not which does not affect debug logic. b0 - Not Supported. b1 - Supported.
  [24] SYS_EXE_REQ — Whether HWA Core Execution status and control is supported. b0 - Not Supported. b1 - Supported.
  [23] TRIG_OUTPUT — b0 - Trigger Outputs are not supported. b1 - Trigger Outputs are supported.
  [22] TRIG_INPUT — b0 - Trigger Inputs are not supported. b1 - Trigger Inputs are supported.
  [21:20] TRIG_CHNS — Number of Trigger Channels Supported. b00 ------ No channels supported. b01 ------ One channel supported. b10 ------ Two channels supported. Others ---- Reserved.
  [19:16] NUM_CNTRS — The number of counter modules that exist. The registers supporting the counter modules must be implemented consecutively in the memory map.
  [15:12] NUM_WPS — The number of watchpoint modules that exist. The registers supporting the watchpoint modules must be implemented consecutively in the memory map
  [11:8] NUM_BPS — The number of breakpoint modules that exist. The registers supporting the breakpoint modules must be implemented consecutively in the memory map.
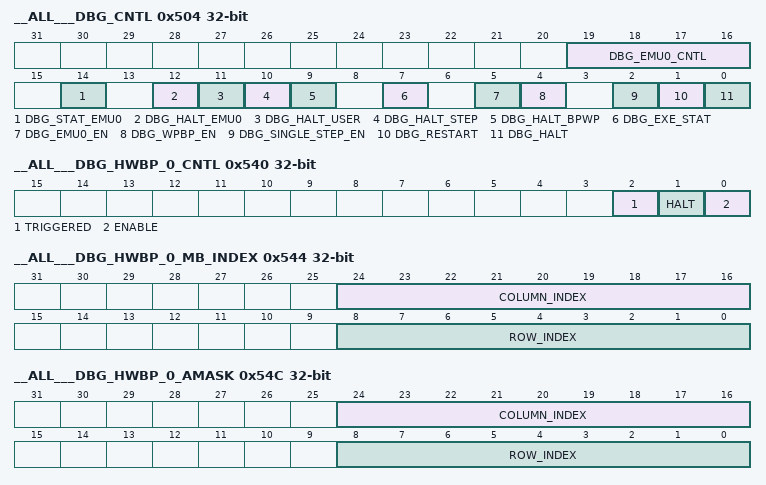
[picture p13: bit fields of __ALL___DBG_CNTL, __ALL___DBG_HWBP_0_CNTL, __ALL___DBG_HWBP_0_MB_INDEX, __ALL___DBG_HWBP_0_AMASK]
0x504 __ALL___DBG_CNTL access per field — Debug Control register is used by debug software to control all of the basic debug functions.
  [19:16] DBG_EMU0_CNTL ro — EMU0 output control. The cross trigger output control. This values in this field determine the behavior of the outputs generated on EMU0. NOTE: The effect of setting ‘1’ is ignored if the HWA Core is currently in HALTED state until the HWA core exits and re-enters HALTED state. DBG_EMUn_CNTL=0, Output Enable=De-asserted, Output=0, Pulse=NA, Description=No output. Input only. DBG_EMUn_CNTL=1, Output Enable=Stopping , Output=0, Pulse=Yes, Description=Pulse on halt. If this bit is set when halted then no effect until the HWA re-enters halted state. DBG_EMUn_CNTL=2, Output Enable=HWBP, Output=0, Pulse=Yes, Description=Pulse when any HWBP triggers. DBG_EMUn_CNTL=3, Output Enable=HWWP, Output=0, Pulse=Yes, Description=Pulse when any HWWP triggers. DBG_EMUn_CNTL=4, Output Enable=Asserted, Output=1, Pulse=No, Description=Drive pin high. DBG_EMUn_CNTL=5, Output Enable=Asserted, Output=0, Pulse=No, Description=Drive pin low. DBG_EMUn_CNTL=6 to 15, Description=Reserved.
  [14] DBG_STAT_EMU0 ro — Statues of EMU0 input. This bit indicates the current value of the EMU0 input.
  [12] DBG_HALT_EMU0 ro — Execution halted due to trigger in on EMU0 input. Set to ‘1’ when halt due to EMU0 input completes. Set to ‘0’ when execution resumes.
  [11] DBG_HALT_USER ro — Execution halted due to an application update of the DBG_HALT bit. Set to ‘1’ when halt due to DBG_HALT update completes. Set to ‘0’ when execution resumes.
  [10] DBG_HALT_STEP ro — Execution halted due to single step completion. Set to ‘1’ when the single step completes. Set to ‘0’ when execution resumes.
  [9] DBG_HALT_BPWP ro — Execution halted due to trigger from HWBP or WP. Set to ‘1’ halt due to breakpoint or watchpoint completes. Set to ‘0’ when execution resumes.
  [7] DBG_EXE_STAT ro — The execution status of the module. Set to ‘1’ when halted due to debug event. Set to ‘0’ when execution resumes.
  [5] DBG_EMU0_EN rw — EMU0 input trigger enable. Writing ‘1’ enables halting on the falling edge of the EMU0 input. Writing ‘0’ disables halts via EMU0 input.
  [4] DBG_WPBP_EN rw — This bit enables the halts on watchpoint or hardware breakpoint trigger events. Writing ‘1’ enables halting on any hardware breakpoint or watchpoint trigger. Each breakpoint or watchpoint resource also has a local enable. Writing ‘0’ disables halts via hardware breakpoints or watchpoints.
  [2] DBG_SINGLE_STEP_EN rw — Single Step Execution enable. When this bit is set, the accelerator core shall be halted upon execution of a single instruction. This is after the accelerator core has left the halted state by clearing the DBG_HALT control bit. Writing ‘1’ enables halting when the next instruction following exit from halted state is executed. Writing ‘0’ disables halts via single step. NOTE: 1. When the accelerator core enters its natural execution state, it may or may not execute an instruction and re-enter HALTED state.
  [1] DBG_RESTART rw — Debug Restart Status bit. This bit is normally set when the DBG_HALT bit transitions from ‘1’ to ‘0’ when the natural execution state is entered. It is a sticky bit. It may also be set when a synchronous run causes the accelerator to leave halted state. Reading ‘1’ means HWA Core exited halted state (at least temporarily). Reading ‘0’ means HWA Core did not exit halted state. Writing ‘1’ shall clear the bit if set. There is no restriction on when it can be cleared. Writing ‘0’ shall have no effect.
  [0] DBG_HALT rw — Global debug run control. The bit will be read as being set upon entry to HALTED state due to halted state being entered because of SWBP, HWBP, HWWP, EMU0 / 1 trigger or manual halt requested through this control. Writing ‘1’ when read ‘0’ shall cause a halt on the next possible halt boundary. Writing ‘0’ when read ‘1’ returns the system to the natural execution state. A synchronous run hardware request has the same effect. Reading ‘1’ means that the halted state has been reached or been requested by the manual halt mechanism. Reading ‘0’ means that the target is in its natural execution state. NOTE: 1. The natural execution state means the FSM state entered prior to last entry into Halted state. 2. This would be the last application requested FSM state unless the DBG_SYS_EXE_REQ control was used to change it.
0x540 __ALL___DBG_HWBP_0_CNTL access per field — Hardware Brakepoint Control for MC FE (at MB-Index)
  [2] TRIGGERED rw — This bit is Set to "1" when HWBP located at the MB_Index in DBG_HWBP_n_MB_Index is executed. Set to ‘1’ when executing the MB index = DBG_HWBP_n_MB_Index. Cleared to ‘0’ by writing ‘1’ to this bit.
  [1] HALT rw — This bit configures the module to generate halt when triggered. Writing ‘1’ enables a HWA halt when triggered. The DBG_CNTL:DBG_HALT_BPWP must also be set for the halt to occur. Writing ‘0’ disables halt upon trigger.
  [0] ENABLE rw — This is the local enable for the hardware breakpoint module. Writing ‘1’ to this bit enables the module to generate an instruction address match trigger. Writing ‘0’ to this bit disables the module.
0x544 __ALL___DBG_HWBP_0_MB_INDEX access per field — Hardware Brakepoint from MC FE: At MB-Index
  [24:16] COLUMN_INDEX rw — Column index of the MB. After processing that MB HWA will halt.
  [8:0] ROW_INDEX rw — Row index of the MB. After processing that MB HWA will halt.
0x54C __ALL___DBG_HWBP_0_AMASK access per field — Hardware Brakepoint: mask for mb-index
  [24:16] COLUMN_INDEX rw — Mask for the column index of DBG_HWBP_n_MB_INDEX
  [8:0] ROW_INDEX rw — Mask for the row index of DBG_HWBP_n_MB_INDEX
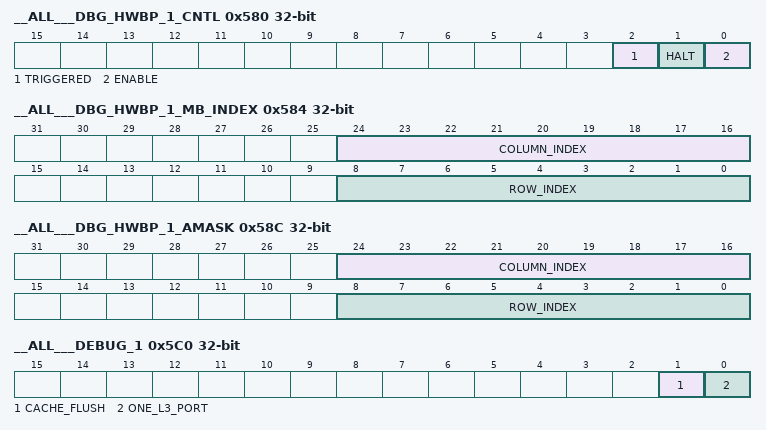
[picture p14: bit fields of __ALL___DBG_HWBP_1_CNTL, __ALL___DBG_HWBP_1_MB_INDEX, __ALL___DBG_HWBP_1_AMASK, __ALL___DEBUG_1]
0x580 __ALL___DBG_HWBP_1_CNTL access per field — Hardware Brakepoint Control for MC BE (at MB-Index)
  fields as __ALL___DBG_HWBP_0_CNTL
0x584 __ALL___DBG_HWBP_1_MB_INDEX access per field — Hardware Brakepoint from MC BE: At MB-Index
  fields as __ALL___DBG_HWBP_0_MB_INDEX
0x58C __ALL___DBG_HWBP_1_AMASK access per field — Hardware Brakepoint: mask for mb-index
  fields as __ALL___DBG_HWBP_0_AMASK
0x5C0 __ALL___DEBUG_1 access per field — MC5 Specific Debug Register 1
  [1] CACHE_FLUSH wo — Writing 1 will clear the horizontal cache; doesn't impact vertical cache; this register should be written when MC5 is in a halted state else output will be corrupted.
  [0] ONE_L3_PORT rw — DMA Operates using only 1 L3 port
0x600 __ALL___GW_REFWINDOW_BC_STATUS ro — Growing Window SL2BC Status
  [31] EMPTY, [27:26] RD_STATUS, [25:16] RD_POINTER, [15] FULL, [11:10] WR_STATUS, [9:0] WR_POINTER
0x608 __ALL___SKIP_BC_STATUS ro — Skip Pred SL2BC Status
  fields as __ALL___GW_REFWINDOW_BC_STATUS
0x60C __ALL___MBHDRINFO_TOP_BC_STATUS ro — MB Info Top SL2BC Status
  fields as __ALL___GW_REFWINDOW_BC_STATUS
0x610 __ALL___MBHDRINFO_BOT_BC_STATUS ro — MB Info Bottom SL2BC Status
  fields as __ALL___GW_REFWINDOW_BC_STATUS
0x614 __ALL___SLICEINFO_BC_STATUS ro — Reference Picture List FIFO Status
  fields as __ALL___GW_REFWINDOW_BC_STATUS
0x618 __ALL___SPARE_BC_0_STATUS ro — SPARE FIFO# 0 Status
  fields as __ALL___GW_REFWINDOW_BC_STATUS
0x620 __ALL___PFC_STATUS ro — PFC LBC Status
  fields as __ALL___GW_REFWINDOW_BC_STATUS
0x624 __ALL___AMT_STATUS ro — AMT LBC Status
  fields as __ALL___GW_REFWINDOW_BC_STATUS
0x628 __ALL___DMA_COMMANDS_STATUS ro — DMA_COMMANDS LBC Status
  fields as __ALL___GW_REFWINDOW_BC_STATUS
0x62C __ALL___DMA_INTADDRESS_STATUS ro — DMA_INTADDRESS LBC Status
  fields as __ALL___GW_REFWINDOW_BC_STATUS
0x630 __ALL___BE_SYNC_STATUS ro — BE_SYNC LBC Status
  fields as __ALL___GW_REFWINDOW_BC_STATUS
{0x634+4i} __ALL___MC_DATA_BANK_LUMA_EVEN_{i}_STATUS ro (i=0..2) — MC_DATA_BANK_LUMA_EVEN_{i} LBC Status
  fields as __ALL___GW_REFWINDOW_BC_STATUS
{0x640+4i} __ALL___MC_DATA_BANK_LUMA_ODD_{i}_STATUS ro (i=0..2) — MC_DATA_BANK_LUMA_ODD_{i} LBC Status
  fields as __ALL___GW_REFWINDOW_BC_STATUS
{0x64C+4i} __ALL___MC_DATA_BANK_CHROMA_EVEN_{i}_STATUS ro (i=0..2) — MC_DATA_BANK_CHROMA_EVEN_{i} LBC Status
  fields as __ALL___GW_REFWINDOW_BC_STATUS
{0x658+4i} __ALL___MC_DATA_BANK_CHROMA_ODD_{i}_STATUS ro (i=0..2) — MC_DATA_BANK_CHROMA_ODD_{i} LBC Status
  fields as __ALL___GW_REFWINDOW_BC_STATUS
0x700 __ALL___Slice_Paremeters_1 ro — Slice Paremeters 1
  [7:6] SliceType, [5:4] Profile, [3] FrameNumLSB, [2] MBAFFframeflag
0x704 __ALL___Slice_Paremeters_2 ro — Slice Paremeters 2
  [31:0] CurrentBotFOC
0x708 __ALL___Slice_Paremeters_3 ro — Slice Paremeters 3
  [31:0] CurrentTopFOC
0x70C __ALL___Slice_Paremeters_4 ro — Slice Paremeters 4
  [31:0] CurrentPOC
0x710 __ALL___MB_Parameters_1 ro — MB Parameters 1
  [18] Mb_field, [4n+5:4n+4] B{n}_8x8_blk_partition_type (n=0..3), [4n+3:4n+2] B{n}_8x8_blk_pred_dir (n=0..3), [1:0] mb_partition_type
0x714 __ALL___MB_Parameters_2 ro — MB Parameters 2
  [24:16] MB_Y, [8:0] MB_X
0x718 __ALL___L3_DATA_FETCH_ENABLE access per field — MMR Register to Enable L3 Data Fetch Statistics
  [1] PORT_1_ENABLE rw — 1=> L3_PORT_1_DATA_FETCH Counter is enabled 0=> disabled
  [0] PORT_0_ENABLE rw — 1=> L3_PORT_0_DATA_FETCH Counter is enabled 0=> disabled
0x71C __ALL___L3_DATA_FETCH_CLEAR access per field — MMR Register to Clear L3 Data Fetch Statistics
  [1] PORT_1_CLEAR wo — Write 1 to Clear L3_PORT_1_DATA_FETCH
  [0] PORT_0_CLEAR wo — Write 1 to Clear L3_PORT_0_DATA_FETCH
0x720 __ALL___L3_PORT_0_DATA_FETCH ro — Amount of Data Fetch in Bytes from MC-DMA L3 Port 0
  [31:0] PORT_0_BYTES
0x724 __ALL___L3_PORT_1_DATA_FETCH ro — Amount of Data Fetch in Bytes from MC-DMA L3 Port 1
  [31:0] PORT_1_BYTES
0x728 __ALL___L3_PORT_0_TAG_USAGE ro — MMR Register indicating which all Tags are used for MC-DMA L3 Port 0
  [n] TAG_{n}_USED (n=0..15) — 0=>Tag {n} is Free; 1=> Tag {n} is Used
0x72C __ALL___L3_PORT_1_TAG_USAGE ro — MMR Register indicating which all Tags are used for MC-DMA L3 Port 1
  [n] TAG_{n}_USED (n=0..15) — 0=>Tag {n} is Free; 1=> Tag {n} is Used
0x740 __ALL___SCHEDULER_STATUS ro — Indicates HWA Status
  [2] PIPEDOWN — HWA is in pipedown
  [1] EXE — HWA is executing
  [0] INIT — HWA is autoloading/initializing
0x744 __ALL___HWA_THREAD_STATUS_FE_PRE ro — FE Pre Thread Status
  [6] HALT_DEBUG_OUT — Halted because of debug out request
  [5] HALT_DEBUG_IN — Halted because of pi_emu
  [4] HALT_REWIND — Halted because of rewind
  [3] HALT_PIPEDOWN — Thread piped down
  [2] HALT_INTR — Halted because of interrupt request
  [1] EXE — Execution state
  [0] WAIT — Waiting for the Tstart_req
0x748 __ALL___HWA_THREAD_STATUS_FE_MAIN ro — FE Main Thread Status
  fields as __ALL___HWA_THREAD_STATUS_FE_PRE
0x74C __ALL___HWA_THREAD_STATUS_DMA ro — DMA Thread Status
  fields as __ALL___HWA_THREAD_STATUS_FE_PRE
0x750 __ALL___HWA_THREAD_STATUS_BE ro — BE Thread Status
  fields as __ALL___HWA_THREAD_STATUS_FE_PRE
0x1000 __ALL___W_BUF_FIRST_0
  [31:0] W_BUF
0x1004 __ALL___W_BUF_FIRST_1
  [31:0] W_BUF
0x13F8 __ALL___W_BUF_LAST_0
  [31:0] W_BUF
0x13FC __ALL___W_BUF_LAST_1
  [31:0] W_BUF
0x1800 __ALL___RA_BUF_FIRST
  [31:0] RA_BUF
0x1EFC __ALL___RA_BUF_LAST
  [31:0] RA_BUF
0x2000 __ALL___SA_MEM_FIRST_0
  [31:0] SA_MEM
0x2004 __ALL___SA_MEM_FIRST_1 access per field
  [11:0] SA_MEM rw
0x31F8 __ALL___SA_MEM_LAST_0
  [31:0] SA_MEM
0x31FC __ALL___SA_MEM_LAST_1 access per field
  [11:0] SA_MEM rw
0x4000 __ALL___VC_TAGS_FIRST access per field
  [15:0] VC_TAGS rw
0x4FFC __ALL___VC_TAGS_LAST access per field
  [15:0] VC_TAGS rw
0x6000 __ALL___PFC_FIRST_0
  [31:0] PFC
0x6004 __ALL___PFC_FIRST_1
  [31:0] PFC
0x6008 __ALL___PFC_FIRST_2 access per field
  [7:0] PFC rw
0x83F0 __ALL___PFC_LAST_0
  [31:0] PFC
0x83F4 __ALL___PFC_LAST_1
  [31:0] PFC
0x83F8 __ALL___PFC_LAST_2 access per field
  [7:0] PFC rw
{0x9B00+0x2000*i} __ALL___AMT{i}_FIRST_0 (i=0..2)
  [31:0] AMT
{0x9B04+0x2000*i} __ALL___AMT{i}_FIRST_1 access per field (i=0..2)
  [11:0] AMT rw
{0xB2F8+0x2000*i} __ALL___AMT{i}_LAST_0 (i=0..2)
  [31:0] AMT
{0xB2FC+0x2000*i} __ALL___AMT{i}_LAST_1 access per field (i=0..2)
  [11:0] AMT rw
0x11B00 __ALL___DMA_COMMANDS0_FIRST_0
  [31:0] DMA_COMMANDS
0x11B04 __ALL___DMA_COMMANDS0_FIRST_1
  [31:0] DMA_COMMANDS
0x11B08 __ALL___DMA_COMMANDS0_FIRST_2 access per field
  [9:0] DMA_COMMANDS rw
0x13330 __ALL___DMA_COMMANDS0_LAST_0
  [31:0] DMA_COMMANDS
0x13334 __ALL___DMA_COMMANDS0_LAST_1
  [31:0] DMA_COMMANDS
0x13338 __ALL___DMA_COMMANDS0_LAST_2 access per field
  [9:0] DMA_COMMANDS rw
0x13B00 __ALL___DMA_COMMANDS1_FIRST_0
  [31:0] DMA_COMMANDS
0x13B04 __ALL___DMA_COMMANDS1_FIRST_1
  [31:0] DMA_COMMANDS
0x13B08 __ALL___DMA_COMMANDS1_FIRST_2 access per field
  [9:0] DMA_COMMANDS rw
0x15330 __ALL___DMA_COMMANDS1_LAST_0
  [31:0] DMA_COMMANDS
0x15334 __ALL___DMA_COMMANDS1_LAST_1
  [31:0] DMA_COMMANDS
0x15338 __ALL___DMA_COMMANDS1_LAST_2 access per field
  [9:0] DMA_COMMANDS rw
0x19B00 __ALL___DMA_INTADDRESS0_FIRST_0
  [31:0] DMA_INTADDRESS
0x19B04 __ALL___DMA_INTADDRESS0_FIRST_1
  [31:0] DMA_INTADDRESS
0x19B08 __ALL___DMA_INTADDRESS0_FIRST_2 access per field
  [15:0] DMA_INTADDRESS rw
0x1A110 __ALL___DMA_INTADDRESS0_LAST_0
  [31:0] DMA_INTADDRESS
0x1A114 __ALL___DMA_INTADDRESS0_LAST_1
  [31:0] DMA_INTADDRESS
0x1A118 __ALL___DMA_INTADDRESS0_LAST_2 access per field
  [15:0] DMA_INTADDRESS rw
0x1A300 __ALL___DMA_INTADDRESS1_FIRST_0
  [31:0] DMA_INTADDRESS
0x1A304 __ALL___DMA_INTADDRESS1_FIRST_1
  [31:0] DMA_INTADDRESS
0x1A308 __ALL___DMA_INTADDRESS1_FIRST_2 access per field
  [15:0] DMA_INTADDRESS rw
0x1A910 __ALL___DMA_INTADDRESS1_LAST_0
  [31:0] DMA_INTADDRESS
0x1A914 __ALL___DMA_INTADDRESS1_LAST_1
  [31:0] DMA_INTADDRESS
0x1A918 __ALL___DMA_INTADDRESS1_LAST_2 access per field
  [15:0] DMA_INTADDRESS rw
{0x1E000+4i} __ALL___MC_DATA_BANK_LUMA_EVEN_0_FIRST_{i} (i=0..3)
  [31:0] MC_DATA_BANK_LUMA_EVEN_0
{0x1E7F0+4i} __ALL___MC_DATA_BANK_LUMA_EVEN_0_LAST_{i} (i=0..3)
  [31:0] MC_DATA_BANK_LUMA_EVEN_0
{0x1F000+4i} __ALL___MC_DATA_BANK_LUMA_EVEN_1_FIRST_{i} (i=0..3)
  [31:0] MC_DATA_BANK_LUMA_EVEN_1
{0x1F7F0+4i} __ALL___MC_DATA_BANK_LUMA_EVEN_1_LAST_{i} (i=0..3)
  [31:0] MC_DATA_BANK_LUMA_EVEN_1
{0x20000+4i} __ALL___MC_DATA_BANK_LUMA_EVEN_2_FIRST_{i} (i=0..3)
  [31:0] MC_DATA_BANK_LUMA_EVEN_2
{0x207F0+4i} __ALL___MC_DATA_BANK_LUMA_EVEN_2_LAST_{i} (i=0..3)
  [31:0] MC_DATA_BANK_LUMA_EVEN_2
{0x24000+4i} __ALL___MC_DATA_BANK_LUMA_ODD_0_FIRST_{i} (i=0..3)
  [31:0] MC_DATA_BANK_LUMA_ODD_0
{0x247F0+4i} __ALL___MC_DATA_BANK_LUMA_ODD_0_LAST_{i} (i=0..3)
  [31:0] MC_DATA_BANK_LUMA_ODD_0
{0x25000+4i} __ALL___MC_DATA_BANK_LUMA_ODD_1_FIRST_{i} (i=0..3)
  [31:0] MC_DATA_BANK_LUMA_ODD_1
{0x257F0+4i} __ALL___MC_DATA_BANK_LUMA_ODD_1_LAST_{i} (i=0..3)
  [31:0] MC_DATA_BANK_LUMA_ODD_1
{0x26000+4i} __ALL___MC_DATA_BANK_LUMA_ODD_2_FIRST_{i} (i=0..3)
  [31:0] MC_DATA_BANK_LUMA_ODD_2
{0x267F0+4i} __ALL___MC_DATA_BANK_LUMA_ODD_2_LAST_{i} (i=0..3)
  [31:0] MC_DATA_BANK_LUMA_ODD_2
{0x2A000+4i} __ALL___MC_DATA_BANK_CHROMA_EVEN_0_FIRST_{i} (i=0..3)
  [31:0] MC_DATA_BANK_CHROMA_EVEN_0
{0x2A3F0+4i} __ALL___MC_DATA_BANK_CHROMA_EVEN_0_LAST_{i} (i=0..3)
  [31:0] MC_DATA_BANK_CHROMA_EVEN_0
{0x2A800+4i} __ALL___MC_DATA_BANK_CHROMA_EVEN_1_FIRST_{i} (i=0..3)
  [31:0] MC_DATA_BANK_CHROMA_EVEN_1
{0x2ABF0+4i} __ALL___MC_DATA_BANK_CHROMA_EVEN_1_LAST_{i} (i=0..3)
  [31:0] MC_DATA_BANK_CHROMA_EVEN_1
{0x2B000+4i} __ALL___MC_DATA_BANK_CHROMA_EVEN_2_FIRST_{i} (i=0..3)
  [31:0] MC_DATA_BANK_CHROMA_EVEN_2
{0x2B3F0+4i} __ALL___MC_DATA_BANK_CHROMA_EVEN_2_LAST_{i} (i=0..3)
  [31:0] MC_DATA_BANK_CHROMA_EVEN_2
{0x2D000+4i} __ALL___MC_DATA_BANK_CHROMA_ODD_0_FIRST_{i} (i=0..3)
  [31:0] MC_DATA_BANK_CHROMA_ODD_0
{0x2D3F0+4i} __ALL___MC_DATA_BANK_CHROMA_ODD_0_LAST_{i} (i=0..3)
  [31:0] MC_DATA_BANK_CHROMA_ODD_0
{0x2D800+4i} __ALL___MC_DATA_BANK_CHROMA_ODD_1_FIRST_{i} (i=0..3)
  [31:0] MC_DATA_BANK_CHROMA_ODD_1
{0x2DBF0+4i} __ALL___MC_DATA_BANK_CHROMA_ODD_1_LAST_{i} (i=0..3)
  [31:0] MC_DATA_BANK_CHROMA_ODD_1
{0x2E000+4i} __ALL___MC_DATA_BANK_CHROMA_ODD_2_FIRST_{i} (i=0..3)
  [31:0] MC_DATA_BANK_CHROMA_ODD_2
{0x2E3F0+4i} __ALL___MC_DATA_BANK_CHROMA_ODD_2_LAST_{i} (i=0..3)
  [31:0] MC_DATA_BANK_CHROMA_ODD_2
0x1BB000 __ALL___BE_SYNC_FIRST access per field
  [1:0] BE_SYNC rw
0x1BB004 __ALL___BE_SYNC_LAST access per field
  [1:0] BE_SYNC rw
